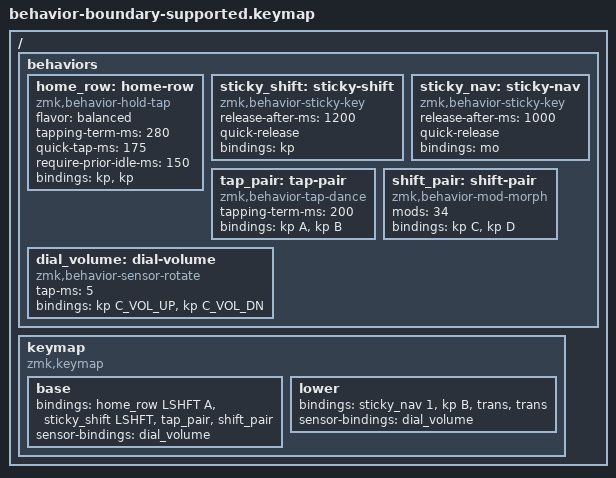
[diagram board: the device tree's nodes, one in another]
/*
 * CHG-006 Phase 1 specification input, not behavior-authoring acceptance.
 * Synthetic generic names only; no concrete keyboard or host board.
 * Intended editable schemas for the supported families: hold-tap, sticky-key,
 * sticky-layer (a sticky-key whose child is a momentary layer), tap-dance,
 * mod-morph and sensor-rotate. Not firmware-build evidence.
 */
#include <behaviors.dtsi>
#include <dt-bindings/zmk/keys.h>
#include <dt-bindings/zmk/modifiers.h>

/ {
    behaviors {
        home_row: home-row {
            compatible = "zmk,behavior-hold-tap";
            #binding-cells = <2>;
            flavor = "balanced";
            tapping-term-ms = <280>;
            quick-tap-ms = <175>;
            require-prior-idle-ms = <150>;
            bindings = <&kp>, <&kp>;
        };

        sticky_shift: sticky-shift {
            compatible = "zmk,behavior-sticky-key";
            #binding-cells = <1>;
            release-after-ms = <1200>;
            quick-release;
            bindings = <&kp>;
        };

        sticky_nav: sticky-nav {
            compatible = "zmk,behavior-sticky-key";
            #binding-cells = <1>;
            release-after-ms = <1000>;
            quick-release;
            bindings = <&mo>;
        };

        tap_pair: tap-pair {
            compatible = "zmk,behavior-tap-dance";
            #binding-cells = <0>;
            tapping-term-ms = <200>;
            bindings = <&kp A>, <&kp B>;
        };

        shift_pair: shift-pair {
            compatible = "zmk,behavior-mod-morph";
            #binding-cells = <0>;
            mods = <34>;
            bindings = <&kp C>, <&kp D>;
        };

        dial_volume: dial-volume {
            compatible = "zmk,behavior-sensor-rotate";
            #sensor-binding-cells = <0>;
            tap-ms = <5>;
            bindings = <&kp C_VOL_UP>, <&kp C_VOL_DN>;
        };
    };

    keymap {
        compatible = "zmk,keymap";
        base {
            bindings = <&home_row LSHFT A &sticky_shift LSHFT &tap_pair &shift_pair>;
            sensor-bindings = <&dial_volume>;
        };
        lower {
            bindings = <&sticky_nav 1 &kp B &trans &trans>;
            sensor-bindings = <&dial_volume>;
        };
    };
};
